AUTOSAR XML (schema 00044)
package /ComponentTypes
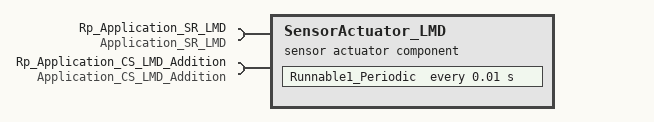
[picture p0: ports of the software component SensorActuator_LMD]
  sensor actuator sw component type SensorActuator_LMD
    require port Rp_Application_SR_LMD: nonqueued-receiver-com-spec{data-element=Element, filter=data-filter-type=ALWAYS}, required-interface=Application_SR_LMD
    require port Rp_Application_CS_LMD_Addition: client-com-spec=OIE_CS_LMD, required-interface=Application_CS_LMD_Addition
    behavior SensorActuator_LMD_InternalBehavior
      timing event TMT_Runnable1_Periodic: start-on-event=Runnable1_Periodic, period=0.01
      runnable Runnable1_Periodic
        data-read-access:
          access READ_Rp_Application_SR_LMD_Element: accessed-variable=Rp_Application_SR_LMD.Element
        sync call SC_Application_CS_LMD_Addition_OIE_CS_LMD: operation=Rp_Application_CS_LMD_Addition.OIE_CS_LMD
  swc implementation SensorActuator_LMD_Implementation: behavior=SensorActuator_LMD_InternalBehavior
